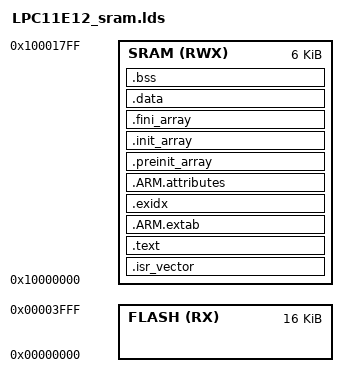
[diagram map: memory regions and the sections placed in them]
/* Generated by LinkerScriptGenerator [http://visualgdb.com/tools/LinkerScriptGenerator]
 * Target: LPC11E12
 * The file is provided under the BSD license.
 */

ENTRY(Reset_Handler)

MEMORY
{
	FLASH (RX) : ORIGIN = 0x00000000, LENGTH = 16K
	SRAM (RWX) : ORIGIN = 0x10000000, LENGTH = 6K
}

_estack = 0x10001800;

SECTIONS
{
	.isr_vector :
	{
		. = ALIGN(4);
		KEEP(*(.isr_vector))
		. = ALIGN(4);
	} > SRAM

	.text :
	{
		. = ALIGN(4);
		_stext = .;

		*(.text)
		*(.text*)
		*(.rodata)
		*(.rodata*)
		*(.glue_7)
		*(.glue_7t)
		KEEP(*(.init))
		KEEP(*(.fini))
		. = ALIGN(4);
		_etext = .;

	} > SRAM

	.ARM.extab :
	{
		. = ALIGN(4);
		*(.ARM.extab)
		*(.gnu.linkonce.armextab.*)
		. = ALIGN(4);
	} > SRAM

	.exidx :
	{
		. = ALIGN(4);
		PROVIDE(__exidx_start = .);
		*(.ARM.exidx*)
		. = ALIGN(4);
		PROVIDE(__exidx_end = .);
	} > SRAM

	.ARM.attributes :
	{
		*(.ARM.attributes)
	} > SRAM

	.preinit_array :
	{
		PROVIDE(__preinit_array_start = .);
		KEEP(*(.preinit_array*))
		PROVIDE(__preinit_array_end = .);
	} > SRAM

	.init_array :
	{
		PROVIDE(__init_array_start = .);
		KEEP(*(SORT(.init_array.*)))
		KEEP(*(.init_array*))
		PROVIDE(__init_array_end = .);
	} > SRAM

	.fini_array :
	{
		PROVIDE(__fini_array_start = .);
		KEEP(*(.fini_array*))
		KEEP(*(SORT(.fini_array.*)))
		PROVIDE(__fini_array_end = .);
	} > SRAM

	.data :
	{
		. = ALIGN(4);
		_sidata = .;

		_sdata = _sidata;

		PROVIDE(__data_start__ = _sdata);
		*(.data)
		*(.data*)
		. = ALIGN(4);
		_edata = .;

		PROVIDE(__data_end__ = _edata);
	} > SRAM

	.bss :
	{
		. = ALIGN(4);
		_sbss = .;

		PROVIDE(__bss_start__ = _sbss);
		*(.bss)
		*(.bss*)
		*(COMMON)
		. = ALIGN(4);
		_ebss = .;

		PROVIDE(__bss_end__ = _ebss);
	} > SRAM

	PROVIDE(end = .);

}

